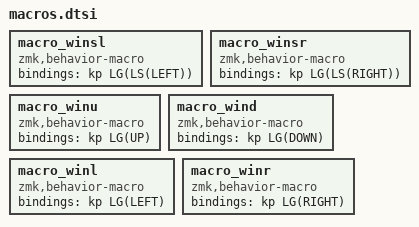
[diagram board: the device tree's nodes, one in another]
macro_winsl: macro_winsl {
  compatible = "zmk,behavior-macro";
  #binding-cells = <0>;
  bindings = <&kp LG(LS(LEFT))>;
};
macro_winsr: macro_winsr {
  compatible = "zmk,behavior-macro";
  #binding-cells = <0>;
  bindings = <&kp LG(LS(RIGHT))>;
};
macro_winu: macro_winu {
  compatible = "zmk,behavior-macro";
  #binding-cells = <0>;
  bindings = <&kp LG(UP)>;
};
macro_wind: macro_wind {
  compatible = "zmk,behavior-macro";
  #binding-cells = <0>;
  bindings = <&kp LG(DOWN)>;
};
macro_winl: macro_winl {
  compatible = "zmk,behavior-macro";
  #binding-cells = <0>;
  bindings = <&kp LG(LEFT)>;
};
macro_winr: macro_winr {
  compatible = "zmk,behavior-macro";
  #binding-cells = <0>;
  bindings = <&kp LG(RIGHT)>;
};
